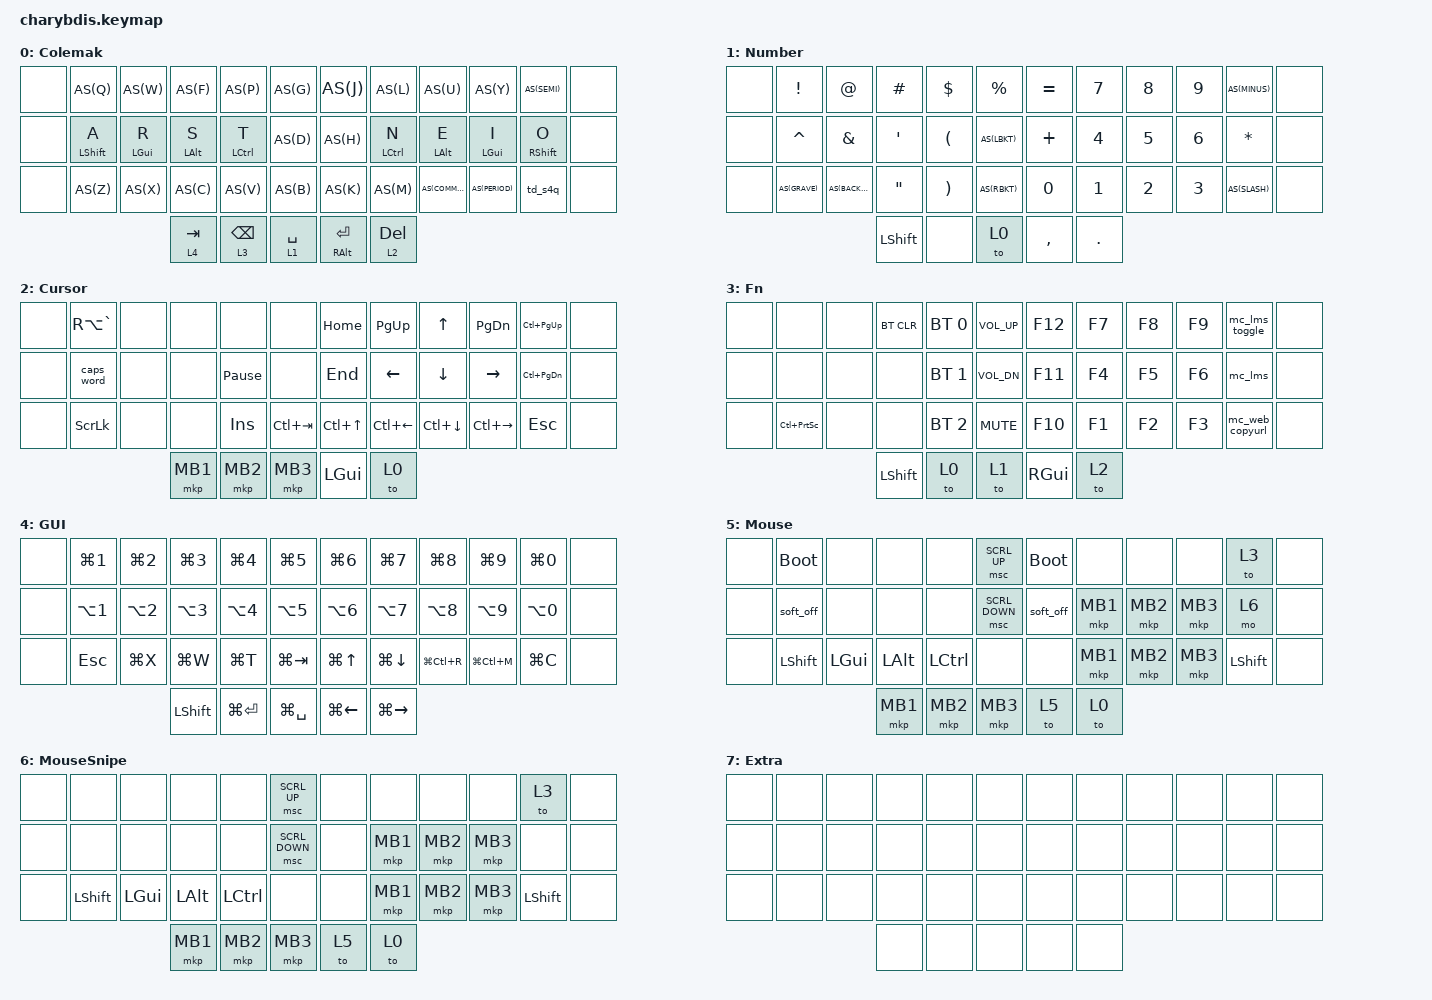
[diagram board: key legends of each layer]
#include <behaviors/mouse_keys.dtsi>
#include <behaviors.dtsi>
#include <dt-bindings/zmk/bt.h>
#include <dt-bindings/zmk/keys.h>
#include <dt-bindings/zmk/mouse.h>
#include <dt-bindings/zmk/outputs.h>


#define AS(keycode) &as LS(keycode) keycode


&lt {
    tapping-term-ms = <200>;
    flavor = "balanced";
    require-prior-idle-ms = <130>;
    quick-tap-ms = <150>;
};

&mt {
    tapping-term-ms = <200>;
    flavor = "balanced";
    require-prior-idle-ms = <130>;
    quick-tap-ms = <150>;
    retro-tap;
};


/ {
    // Behaviors
    behaviors {
        as: auto_shift {
            compatible = "zmk,behavior-hold-tap";
            #binding-cells = <2>;
            tapping_term_ms = <160>;
            quick_tap_ms = <0>;
            flavor = "tap-preferred";
            bindings = <&kp>, <&kp>;
        };

        td_s4q: tap_dance_mod_tap {
            compatible = "zmk,behavior-tap-dance";
            #binding-cells = <0>;
            tapping-term-ms = <200>;
            bindings = <&lt 4 SLASH>, <&kp QMARK>;
        };
    };

    // Macros
    macros {
        mc_lms_toggle: mc_lms_toggle {
            label = "MC_LMS_TOGGLE";
            compatible = "zmk,behavior-macro";
            #binding-cells = <0>;
            bindings = <&kp LG(S) &kp SPACE>;
        };

        mc_lms: mc_lms {
            label = "MC_LMS";
            compatible = "zmk,behavior-macro";
            #binding-cells = <0>;
            bindings = <&kp LG(S) &kp S>;
        };

        mc_web_copyurl: mc_web_copyurl {
            label = "MC_WEB_COPYURL";
            compatible = "zmk,behavior-macro";
            #binding-cells = <0>;
            bindings = <&kp LC(L)>, <&macro_wait_time 50>, <&kp LC(C) &kp F6>;
        };
    };

   // Combos
   combos {
        compatible = "zmk,combos";
        combo_f12 {
            timeout-ms = <50>;
            key-positions = <6 7>;
            bindings = <&kp F12>;
        };
        combo_f11 {
            timeout-ms = <50>;
            key-positions = <6 18>;
            bindings = <&kp F11>;
        };
        combo_f9 {
            timeout-ms = <50>;
            key-positions = <18 30>;
            bindings = <&kp F9>;
        };
        combo_l3 {
            timeout-ms = <50>;
            key-positions = <30 31>;
            bindings = <&mo 3>;
        };
        combo_l5 {
            timeout-ms = <50>;
            key-positions = <5 17>;
            bindings = <&tog 5>;
        };
        combo_mb1 {
            timeout-ms = <50>;
            key-positions = <16 17>;
            bindings = <&mkp MB1>;
        };
    };

    // Keymap
    keymap {
        compatible = "zmk,keymap";

//         Base {
//             label = "Colemak";
//             bindings = <
// &none  &kp Q         &kp W       &kp F       &kp P            &kp G          &kp J           &kp L         &kp U       &kp Y       &kp SEMI      &none
// &none  &mt LSHIFT A  &mt LGUI R  &mt LALT S  &mt LCTRL T      &kp D          &kp H           &mt LCTRL N   &mt LALT E  &mt LGUI I  &mt RSHIFT O  &none
// &none  &kp Z         &kp X       &kp C       &kp V            &kp B          &kp K           &kp M         &kp COMMA   &kp PERIOD  &lt 4 SLASH   &none
//                                  &lt 4 TAB   &lt 3 BACKSPACE  &lt 1 SPACE    &mt RALT ENTER  &lt 2 DELETE
//             >;
//         };

//         Number {
//             label = "Number";
//             bindings = <
// &none  &kp EXCLAMATION  &kp AT         &kp HASH           &kp DLLR  &kp PRCNT    &kp EQUAL     &kp NUMBER_7  &kp NUMBER_8  &kp NUMBER_9  &kp MINUS     &none
// &none  &kp CARET        &kp AMPERSAND  &kp SINGLE_QUOTE   &kp LPAR  &kp LBKT     &kp PLUS      &kp NUMBER_4  &kp NUMBER_5  &kp NUMBER_6  &kp ASTERISK  &none
// &none  &kp GRAVE        &kp BACKSLASH  &kp DOUBLE_QUOTES  &kp RPAR  &kp RBKT     &kp NUMBER_0  &kp NUMBER_1  &kp NUMBER_2  &kp NUMBER_3  &kp SLASH     &none
//                                        &kp LSHIFT         &none     &to 0        &kp COMMA     &kp PERIOD
//             >;
//         };

        Base {
            label = "Colemak";
            bindings = <
&none  AS(Q)         AS(W)       AS(F)       AS(P)            AS(G)          AS(J)           AS(L)         AS(U)       AS(Y)       AS(SEMI)      &none
&none  &mt LSHIFT A  &mt LGUI R  &mt LALT S  &mt LCTRL T      AS(D)          AS(H)           &mt LCTRL N   &mt LALT E  &mt LGUI I  &mt RSHIFT O  &none
&none  AS(Z)         AS(X)       AS(C)       AS(V)            AS(B)          AS(K)           AS(M)         AS(COMMA)   AS(PERIOD)  &td_s4q       &none
                                 &lt 4 TAB   &lt 3 BACKSPACE  &lt 1 SPACE    &mt RALT ENTER  &lt 2 DELETE
            >;
        };

        Number {
            label = "Number";
            bindings = <
&none  &kp EXCLAMATION  &kp AT         &kp HASH           &kp DLLR  &kp PRCNT    &kp EQUAL     &kp NUMBER_7  &kp NUMBER_8  &kp NUMBER_9  AS(MINUS)     &none
&none  &kp CARET        &kp AMPERSAND  &kp SINGLE_QUOTE   &kp LPAR  AS(LBKT)     &kp PLUS      &kp NUMBER_4  &kp NUMBER_5  &kp NUMBER_6  &kp ASTERISK  &none
&none  AS(GRAVE)        AS(BACKSLASH)  &kp DOUBLE_QUOTES  &kp RPAR  AS(RBKT)     &kp NUMBER_0  &kp NUMBER_1  &kp NUMBER_2  &kp NUMBER_3  AS(SLASH)     &none
                                       &kp LSHIFT         &none     &to 0        &kp COMMA     &kp PERIOD
            >;
        };

        Cursor {
            label = "Cursor";
            bindings = <
&none  &kp RA(GRAVE)  &none  &none     &none            &none          &kp HOME    &kp PG_UP     &kp UP        &kp PG_DN      &kp LC(PG_UP)  &none
&none  &caps_word     &none  &none     &kp PAUSE_BREAK  &none          &kp END     &kp LEFT      &kp DOWN      &kp RIGHT      &kp LC(PG_DN)  &none
&none  &kp SLCK       &none  &none     &kp INSERT       &kp LC(TAB)    &kp LC(UP)  &kp LC(LEFT)  &kp LC(DOWN)  &kp LC(RIGHT)  &kp ESC        &none
                             &mkp MB1  &mkp MB2         &mkp MB3       &kp LGUI    &to 0
            >;
        };

        Fn_keys {
            label = "Fn";
            bindings = <
&none  &none          &none  &bt BT_CLR  &bt BT_SEL 0  &kp C_VOL_UP    &kp F12   &kp F7  &kp F8  &kp F9  &mc_lms_toggle   &none
&none  &none          &none  &none       &bt BT_SEL 1  &kp C_VOL_DN    &kp F11   &kp F4  &kp F5  &kp F6  &mc_lms          &none
&none  &kp LC(PSCRN)  &none  &none       &bt BT_SEL 2  &kp C_MUTE      &kp F10   &kp F1  &kp F2  &kp F3  &mc_web_copyurl  &none
                             &kp LSHIFT  &to 0         &to 1           &kp RGUI  &to 2
            >;
        };

        GUI_keys {
            label = "GUI";
            bindings = <
&none  &kp LG(N1)  &kp LG(N2)  &kp LG(N3)  &kp LG(N4)     &kp LG(N5)       &kp LG(N6)    &kp LG(N7)     &kp LG(N8)     &kp LG(N9)     &kp LG(N0)  &none
&none  &kp LA(N1)  &kp LA(N2)  &kp LA(N3)  &kp LA(N4)     &kp LA(N5)       &kp LA(N6)    &kp LA(N7)     &kp LA(N8)     &kp LA(N9)     &kp LA(N0)  &none
&none  &kp ESC     &kp LG(X)   &kp LG(W)   &kp LG(T)      &kp LG(TAB)      &kp LG(UP)    &kp LG(DOWN)   &kp LG(LC(R))  &kp LG(LC(M))  &kp LG(C)   &none
                               &kp LSHIFT  &kp LG(ENTER)  &kp LG(SPACE)    &kp LG(LEFT)  &kp LG(RIGHT)
            >;
        };

        Mouse {
            label = "Mouse";
            bindings = <
&none  &bootloader  &none     &none     &none      &msc SCRL_UP      &bootloader  &none     &none     &none     &to 3       &none
&none  &soft_off    &none     &none     &none      &msc SCRL_DOWN    &soft_off    &mkp MB1  &mkp MB2  &mkp MB3  &mo 6       &none
&none  &kp LSHIFT   &kp LGUI  &kp LALT  &kp LCTRL  &none             &none        &mkp MB1  &mkp MB2  &mkp MB3  &kp LSHIFT  &none
                              &mkp MB1  &mkp MB2   &mkp MB3          &to 5        &to 0
            >;
        };

        MouseSnipe {
            label = "MouseSnipe";
            bindings = <
&none  &none       &none     &none     &none      &msc SCRL_UP      &none  &none     &none     &none     &to 3       &none
&none  &none       &none     &none     &none      &msc SCRL_DOWN    &none  &mkp MB1  &mkp MB2  &mkp MB3  &none       &none
&none  &kp LSHIFT  &kp LGUI  &kp LALT  &kp LCTRL  &none             &none  &mkp MB1  &mkp MB2  &mkp MB3  &kp LSHIFT  &none
                             &mkp MB1  &mkp MB2   &mkp MB3          &to 5  &to 0
            >;
        };

        Extra {
            label = "Extra";
            bindings = <
&none  &none  &none  &none  &none  &none    &none  &none  &none  &none  &none  &none
&none  &none  &none  &none  &none  &none    &none  &none  &none  &none  &none  &none
&none  &none  &none  &none  &none  &none    &none  &none  &none  &none  &none  &none
                     &none  &none  &none    &none  &none
            >;
        };

    };
};
